# PIC32CM5112SG00064 register map
Vendor: Microchip Technology; Series: PIC32CMSG00; File version: 0
CPU: CM23 r0p0, little endian, MPU, no FPU, 2 interrupt priority bits, 141 interrupts, 13 SAU regions
Registers are 32-bit, read-write, reset 0x0 unless marked. A register's access mark holds for its fields unless they carry their own. Offsets are from the block's base; [hi:lo] are bit positions.

## PUF — Physically Unclonable Function
Base 0x44834000
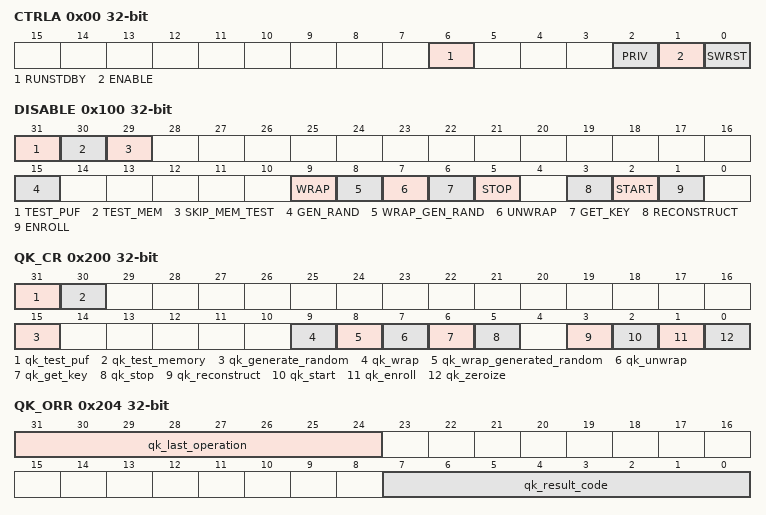
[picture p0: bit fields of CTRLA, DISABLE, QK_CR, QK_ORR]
0x00 CTRLA — Control Register A
  [6] RUNSTDBY — RUNSTDBY Enable bit - not used by EIP HWWriting this register has no affect on the EIPNote: Currently this bit is present, but has no functionality. This bit is part of the IP wrapper but has no use for the EIP.
  [2] PRIV — Privileged Access Only
    0=PUF registers accessible in privileged and unprivileged modes; 1=PUF registers only accessible in privileged mode
  [1] ENABLE — Clock Enable bit
    0=PUF clock is disabled and Macro held in reset and any access to QK register would cause PSLVERR; 1=PUF clock is enabled
  [0] SWRST — Software ResetNOTE: Reset to PUF must be held active long enough to reset complete macro.
    0=No effect; 1=Reset registers and internal state
0x38 STATUSA ro — Status Register A
  [0] BUSY — PUF Busy indicator
    0=Macro can accept commands; 1=Macro has not completed the power up or power down sequence and cannot accept any other commands
0x100 DISABLE write-1-sets — Disable Function Control Register
  [31] TEST_PUF — TEST_PUF Command Disable bit
    0=Command is enabled; 1=Command is disabled
  [30] TEST_MEM — TEST_MEMORY Command Disable bit
    0=Command is enabled; 1=Command is disabled
  [29] SKIP_MEM_TEST — SKIP_MEMORY TEST Command Control bit
    0=Command is enabled / Not Skipped; 1=Command is disabled / Skipped during initialization
  [15] GEN_RAND — GENERATE_RANDOM Command Disable bit
    0=Command is enabled; 1=Command is disabled
  [9] WRAP — WRAP Command Disable bit
    0=Command is enabled; 1=Command is disabled
  [8] WRAP_GEN_RAND — WRAP_GENERATE_RANDOM Command Disable bit
    0=Command is enabled; 1=Command is disabled
  [7] UNWRAP — UNWRAP Command Disable bit
    0=Command is enabled; 1=Command is disabled
  [6] GET_KEY — GET_KEY Command Disable bit
    0=Command is enabled; 1=Command is disabled
  [5] STOP — STOP Command Disable bit
    0=Command is enabled; 1=Command is disabled
  [3] RECONSTRUCT — RECONSTRUCT Command Disable bit
    0=Command is enabled; 1=Command is disabled
  [2] START — START Command Disable bit
    0=Command is enabled; 1=Command is disabled
  [1] ENROLL — ENROLL Command Disable bit
    0=Command is enabled; 1=Command is disabled
0x104 RESTRICT0 write-1-sets — Restrict User Context 0 Control Register
  [31:0] RESTRICT_CONTEXT_0 — Restrict User Context Writing a 1 in a bit position prevents other PUF keys to be generated with this context bit set. NOTE: Refer to the EIP datasheet for the function of the restrict_user_context signals
0x108 RESTRICT1 write-1-sets — Restrict User Context 1 Control Register
  [31:0] RESTRICT_CONTEXT_1 — Restrict User Context Writing a 1 in a bit position prevents other PUF keys to be generated with this context bit set. NOTE: Refer to the EIP datasheet for the function of the restrict_user_context signals
0x10C CTRL_PWR — Power Control Register
  [0] SRAM_PWRSW — SRAM Power Switch Enable Bit
    0=SRAM register power is disabled ( puf_req_power_sram driven to 0); 1=SRAM register power is enabled ( puf_req_power_sram driven to 1)
0x110 CTRL_KEY — KEY Control Register
  [0] CLR_PUF_KEY — Clear PUF Key Control Bit
    0=NO Affect; 1=Clears the following outputs from this macro - puf_key, puf_valid, puf_index
0x200 QK_CR — Control register; The Control register defines which command must be executed next. When the command is accepted or rejected, the bits automatically revert to 0. Only one command bit may be written with 1 at a time, with the exception of qk_zeroize. Writing qk_zeroize with 1 takes precedence over all other commands.
  [31] qk_test_puf — Begin Test PUF operation
  [30] qk_test_memory — Begin Test Memory operation
  [15] qk_generate_random — Begin Generate Random operation
  [9] qk_wrap — Begin Wrap operation
  [8] qk_wrap_generated_random — Begin Wrap Generated Random operation
  [7] qk_unwrap — Begin Unwrap operation
  [6] qk_get_key — Begin Get Key operation
  [5] qk_stop — Begin Stop operation
  [3] qk_reconstruct — Begin Reconstruct operation
  [2] qk_start — Begin Start operation
  [1] qk_enroll — Begin Enroll operation
  [0] qk_zeroize — Begin Zeroize operation
0x204 QK_ORR ro — Operation Result register; The Operation Result register provides the result code of the last operation (Initialization, Generate Random, etc.). The value in this register is only valid when qk_busy = 0.
  [31:24] qk_last_operation — Number of last operation
    0=IID_QK_LO_PROGRESS; 1=IID_QK_LO_ENROLL; 2=IID_QK_LO_START; 3=IID_QK_LO_RECONSTRUCT; 5=IID_QK_LO_STOP; 6=IID_QK_LO_GET_KEY; 7=IID_QK_LO_UNWRAP; 8=IID_QK_LO_WRAP_GEN_RND; 9=IID_QK_LO_WRAP; 15=IID_QK_LO_GEN_RND; 30=IID_QK_LO_TEST_MEMORY; 31=IID_QK_LO_TEST_PUF; 32=IID_QK_LO_INITIALIZATION; 47=IID_QK_LO_ZEROIZE
  [7:0] qk_result_code — Result code of last operation
    0=IID_QK_OK; 240=IID_QK_ERR_PRODUCT; 241=IID_QK_ERR_PRODUCT_PH2; 242=IID_QK_ERR_TRANSFER; 243=IID_QK_ERR_TRANSFER_PH2; 244=IID_QK_ERR_AUTH; 245=IID_QK_ERR_AUTH_PH2; 246=IID_QK_ERR_PUF_QUALITY; 247=IID_QK_ERR_CONTEXT; 248=IID_QK_ERR_DESTINATION; 255=IID_QK_FAILURE_SRAM
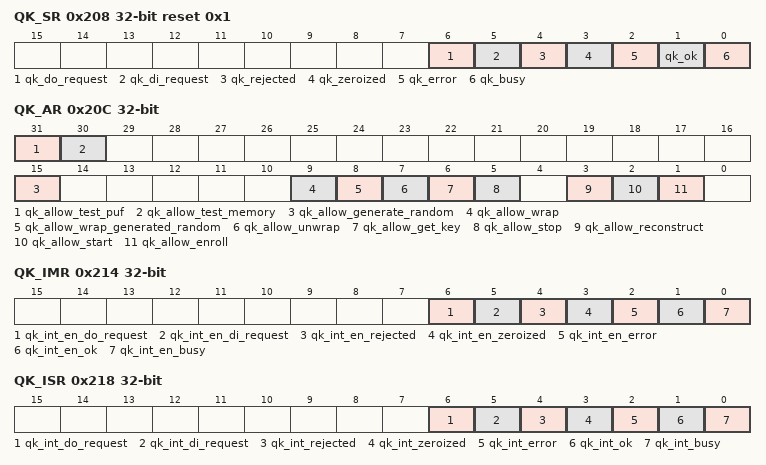
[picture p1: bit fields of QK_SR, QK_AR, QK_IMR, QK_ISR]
0x208 QK_SR reset 0x1 — Status register; The Status register shows the current status of QuiddiKey and indicates whether a data transfer is requested.
  [6] qk_do_request — Request for data out transfer via the QK_DOR register
  [5] qk_di_request — Request for data in transfer via the QK_DIR register
  [4] qk_rejected — Read: Last command was rejected Write 1: Clears this bit
  [3] qk_zeroized — QuiddiKey is in Zeroized or Locked state
  [2] qk_error — Last operation failed
  [1] qk_ok — Last operation was successful
  [0] qk_busy — Operation is in progress
0x20C QK_AR ro — Allow register; The Allow register indicates which operations are currently allowed.
  [31] qk_allow_test_puf — 0: Test PUF operation is not allowed 1: Test PUF operation is allowed
  [30] qk_allow_test_memory — 0: Test Memory operation is not allowed 1: Test Memory operation is allowed
  [15] qk_allow_generate_random — 0: Generate Random operation is not allowed 1: Generate Random operation is allowed
  [9] qk_allow_wrap — 0: Wrap operation is not allowed 1: Wrap operation is allowed
  [8] qk_allow_wrap_generated_random — 0: Wrap Generated Random operation is not allowed 1: Wrap Generated Random operation is allowed
  [7] qk_allow_unwrap — 0: Unwrap operation is not allowed 1: Unwrap operation is allowed
  [6] qk_allow_get_key — 0: Get Key operation is not allowed 1: Get Key operation is allowed
  [5] qk_allow_stop — 0: Stop operation is not allowed 1: Stop operation is allowed
  [3] qk_allow_reconstruct — 0: Reconstruct operation is not allowed 1: Reconstruct operation is allowed
  [2] qk_allow_start — 0: Start operation is not allowed 1: Start operation is allowed
  [1] qk_allow_enroll — 0: Enroll operation is not allowed 1: Enroll operation is allowed
0x210 QK_IER — Interrupt Enable register; With the Interrupt Enable register all QuiddiKey interrupts can be enabled or disabled, without changing the Interrupt Mask register.
  [0] qk_int_en — 0: Disables all QuiddiKey interrupts 1: Enables all QuiddiKey interrupts that are enabled in the Interrupt Mask register
0x214 QK_IMR — Interrupt Mask register; Individual QuiddiKey interrupts can be enabled or disabled with the Interrupt Mask register.
  [6] qk_int_en_do_request — Enables the data out request interrupt
  [5] qk_int_en_di_request — Enables the data in request interrupt
  [4] qk_int_en_rejected — Enables the rejected interrupt
  [3] qk_int_en_zeroized — Enables the zeroized interrupt
  [2] qk_int_en_error — Enables the error interrupt
  [1] qk_int_en_ok — Enables the ok interrupt
  [0] qk_int_en_busy — Enables the busy interrupt
0x218 QK_ISR — Interrupt Status register; The Interrupt Status register indicates which interrupt has occurred. Multiple interrupts may occur at the same time (e.g. the busy interrupt occurs together with one of the ok and error interrupts). Writing 1 to a bit, clears the corresponding bit.
  [6] qk_int_do_request — A positive edge has occurred on qk_do_request, which means that a data out transfer is requested via the QK_DOR register
  [5] qk_int_di_request — A positive edge has occurred on qk_di_request, which means that a data in transfer is requested via the QK_DIR register
  [4] qk_int_rejected — A positive edge has occurred on qk_rejected, which means that a command was rejected
  [3] qk_int_zeroized — A positive edge has occurred on qk_zeroized, which means that QuiddiKey has moved to the Zeroized or Locked state
  [2] qk_int_error — A positive edge has occurred on qk_error, which means that an operation has failed
  [1] qk_int_ok — A positive edge has occurred on qk_ok, which means that an operation successfully completed
  [0] qk_int_busy — A negative edge has occurred on qk_busy, which means that an operation has completed
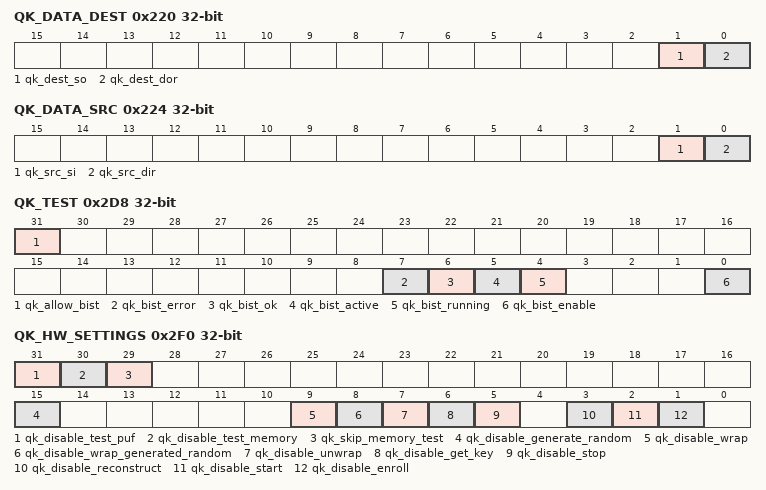
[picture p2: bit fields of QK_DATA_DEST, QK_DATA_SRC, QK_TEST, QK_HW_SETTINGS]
0x220 QK_DATA_DEST — Data Destination register; The Data Destination register defines via which interface data is made available by QuiddiKey. Only one bit at a time may be 1.
  [1] qk_dest_so — Data will be made available via the SO interface
  [0] qk_dest_dor — Data will be made available via the QK_DOR register
0x224 QK_DATA_SRC — Data Source register; The Data Source register defines via which interface data must be provided to QuiddiKey. Combinations of bits may be 1 at a time.
  [1] qk_src_si — Data must be provided via the SI interface
  [0] qk_src_dir — Data must be provided via the QK_DIR register
0x228 QK_KEY_INDEX ro — Key Index register; The Key Index register provides the index of the key that is currently output.
  [3:0] qk_key_inde — Value of the Key Index
0x2A0 QK_DIR wo — Data Input register; The Data Input register is used to transfer data to QuiddiKey. It can only be written when input data is requested (indicated by the qk_di_request signal). When written at any other moment, or when read, an error response is generated. Depending on the way the system is configured and connected, this may generate an exception.
  [31:0] qk_di — Input data to QuiddiKey
0x2A8 QK_DOR ro — Data Output register; The Data Output register is used to transfer data from QuiddiKey. It can only be read when input data is available (indicated by the qk_do_request signal). When read at any other moment, or when written, an error response is generated. Depending on the way the system is configured and connected, this may generate an exception.
  [31:0] qk_do — Output data from QuiddiKey
0x2C0 QK_MISC reset 0x1 — Miscellaneous register; The Miscellaneous register defines miscellaneous settings for QuiddiKey. These usually need to be configured only once after power up orreset.
  [0] qk_data_endianness — Defines the endianness of data in QK_DIR and QK_DOR: 0: Little endian 1: Big endian (default)
0x2D0 QK_IF_SR — Interface Status register; The status of the interface can be monitored with the Interface Status register. Writing 1 to a bit, clears the corresponding bit.
  [0] reg_if_error — An error has occurred at the register interface
0x2D8 QK_TEST — Test register; With the Test register a BIST can be started. It also shows the result of the last BIST.
  [31] qk_allow_bist — BIST is not allowed
  [7] qk_bist_error — BIST has failed
  [6] qk_bist_ok — BIST has passed
  [5] qk_bist_active — BIST is in progress
  [4] qk_bist_running — BIST is in progress or finishing up (after qk_bist_enable = 0)
  [0] qk_bist_enable — Isolates QuiddiKey and runs BIST
0x2DC QK_PSR ro reset 0xF — PUF Score register; The PUF Score register shows the value of the PUF Score that was obtained during the last Test PUF, Enroll, Start or Reconstruct operation.
  [3:0] qk_puf_score — PUF score obtained during the last Test PUF, Enroll, Start or Reconstruct operation
0x2E0 QK_HW_RUC0 ro — Module Restrict User Context 0 register; The Module Restrict User Context 0 register shows the values of the qk_restrict_user_context_0 signal on the signal interface.
  [31:0] qk_restrict_user_context_0 — For each bit in the User_Context_0 field: 0: This bit can be used 1: This bit cannot be used
0x2E4 QK_HW_RUC1 ro — Module Restrict User Context 1 register; The Module Restrict User Context 1 register shows the values of the qk_restrict_user_context_1 signal on the signal interface.
  [31:0] qk_restrict_user_context_1 — For each bit in the User_Context_1 field: 0: This bit can be used 1: This bit cannot be used
0x2F0 QK_HW_SETTINGS ro — Module Settings register; The Module Settings register shows the values of the module settings on the signal interface.
  [31] qk_disable_test_puf — 0: Test PUF operations are enabled 1: Test PUF operations are disabled
  [30] qk_disable_test_memory — 0: Test Memory operations are enabled 1: Test Memory operations are disabled
  [29] qk_skip_memory_test — 0: Includes memory test during initialization 1: Skips memory test during initialization
  [15] qk_disable_generate_random — 0: Generate Random operations are enabled 1: Generate Random operations are disabled
  [9] qk_disable_wrap — 0: Wrap operations are enabled 1: Wrap operations are disabled
  [8] qk_disable_wrap_generated_random — 0: Wrap Generated Random operations are enabled 1: Wrap Generated Random operations are disabled
  [7] qk_disable_unwrap — 0: Unwrap operations are enabled 1: Unwrap operations are disabled
  [6] qk_disable_get_key — 0: Get Key operations are enabled 1: Get Key operations are disabled
  [5] qk_disable_stop — 0: Stop operations are enabled 1: Stop operations are disabled
  [3] qk_disable_reconstruct — 0: Reconstruct operations are enabled 1: Reconstruct operations are disabled
  [2] qk_disable_start — 0: Start operations are enabled 1: Start operations are disabled
  [1] qk_disable_enroll — 0: Enroll operations are enabled 1: Enroll operations are disabled
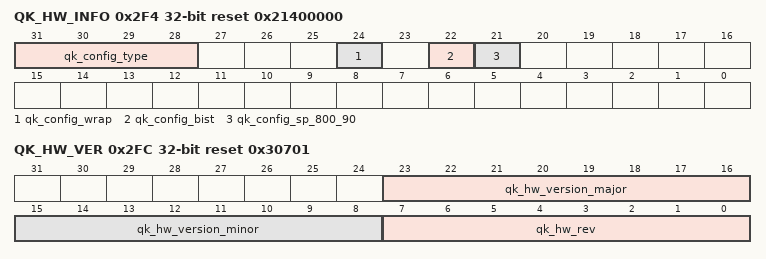
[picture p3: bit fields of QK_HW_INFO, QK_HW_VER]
0x2F4 QK_HW_INFO ro reset 0x21400000 — Module Information register; The Module Information register indicates which configuration of QuiddiKey is used for this module and which options it includes.
  [31:28] qk_config_type — QuiddiKey configuration
    1=IID_QK_SAFE; 2=IID_QK_PLUS
  [24] qk_config_wrap — 1: Wrap is included 0: Wrap is not included
  [22] qk_config_bist — 1: BIST is included 0: BIST is not included
  [21] qk_config_sp_800_90 — 1: SP 800-90 option is included 0: SP 800-90 option is not included
0x2F8 QK_HW_ID ro reset 0x20120702 — Module Identifier register; The Module Identifier register provides the identifier of the QuiddiKey Engine netlist.
  [31:0] qk_hw_id — Module identifier
0x2FC QK_HW_VER ro reset 0x30701 — Module Version register; The Module Version register provides the version of this module: major.minor.patch.
  [23:16] qk_hw_version_major — Module version, major part
  [15:8] qk_hw_version_minor — Module version, minor part
  [7:0] qk_hw_rev — Module version, patch part

## Notices in the file
Copyright (c) 2026 Microchip Technology Inc.
SPDX-License-Identifier: Apache-2.0
Licensed under the Apache License, Version 2.0 (the "License");
you may not use this file except in compliance with the License.
You may obtain a copy of the License at
http://www.apache.org/licenses/LICENSE-2.0
Unless required by applicable law or agreed to in writing, software
distributed under the License is distributed on an "AS IS" BASIS,
WITHOUT WARRANTIES OR CONDITIONS OF ANY KIND, either express or implied.
See the License for the specific language governing permissions and
limitations under the License.
